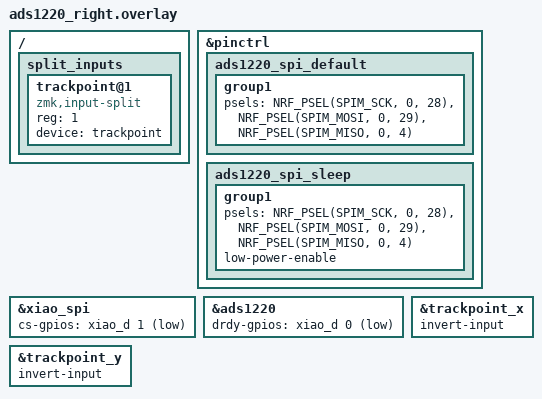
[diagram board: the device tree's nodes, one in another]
/*
 * Right half, ADS1220 pins (U2 in pcb/atlas-right.kicad_pcb):
 *   SCLK D2 (P0.28)   DIN D3 (P0.29)   DOUT D4 (P0.04)   CS D1 (P0.03)   DRDY D0 (P0.02)
 * D8-D10, the XIAO's default SPI pins, are matrix columns here.
 */
#include "ads1220.dtsi"

&pinctrl {
    ads1220_spi_default: ads1220_spi_default {
        group1 {
            psels = <NRF_PSEL(SPIM_SCK, 0, 28)>,
                    <NRF_PSEL(SPIM_MOSI, 0, 29)>,
                    <NRF_PSEL(SPIM_MISO, 0, 4)>;
        };
    };

    ads1220_spi_sleep: ads1220_spi_sleep {
        group1 {
            psels = <NRF_PSEL(SPIM_SCK, 0, 28)>,
                    <NRF_PSEL(SPIM_MOSI, 0, 29)>,
                    <NRF_PSEL(SPIM_MISO, 0, 4)>;
            low-power-enable;
        };
    };
};

&xiao_spi {
    cs-gpios = <&xiao_d 1 GPIO_ACTIVE_LOW>;
};

&ads1220 {
    drdy-gpios = <&xiao_d 0 (GPIO_ACTIVE_LOW | GPIO_PULL_UP)>;
};

/* The stick sits turned 180 degrees on this half: both axes change sign. */
&trackpoint_x {
    invert-input;
};

&trackpoint_y {
    invert-input;
};

/ {
    /* Pointer events to the left half (the central) over the BLE split; the
     * reg only has to match the one in ads1220_left.overlay. */
    split_inputs {
        #address-cells = <1>;
        #size-cells = <0>;

        trackpoint@1 {
            compatible = "zmk,input-split";
            reg = <1>;
            device = <&trackpoint>;
        };
    };
};
